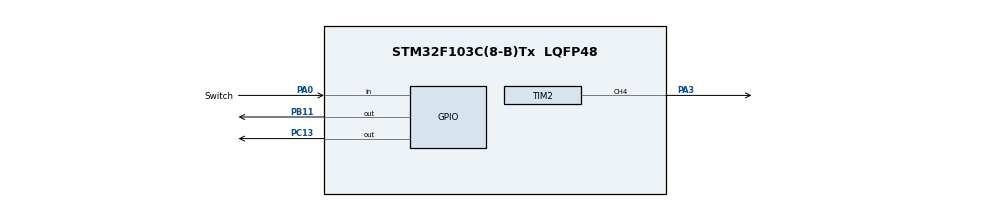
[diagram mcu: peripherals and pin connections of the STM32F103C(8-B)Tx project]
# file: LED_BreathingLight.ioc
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Mcu.Family=STM32F1
Mcu.Name=STM32F103C(8-B)Tx
Mcu.Package=LQFP48
NVIC.PriorityGroup=NVIC_PRIORITYGROUP_4
PA0-WKUP.GPIO_Label=Switch
PA0-WKUP.GPIO_PuPd=GPIO_NOPULL
PA0-WKUP.Signal=GPIO_Input
PA3.Signal=S_TIM2_CH4
PB11.Signal=GPIO_Output
PC13-TAMPER-RTC.GPIO_PuPd=GPIO_NOPULL
PC13-TAMPER-RTC.Signal=GPIO_Output
ProjectManager.HeapSize=0x200
ProjectManager.StackSize=0x400
ProjectManager.TargetToolchain=MDK-ARM V5.27
RCC.APB1Freq_Value=8000000
RCC.APB2CLKDivider=RCC_HCLK_DIV2
RCC.APB2Freq_Value=4000000
RCC.APB2TimFreq_Value=8000000
SH.S_TIM2_CH4.0=TIM2_CH4,PWM Generation4 CH4
TIM2.Channel-PWM\ Generation4\ CH4=TIM_CHANNEL_4
TIM2.Prescaler=1200-1
VP_SYS_VS_ND.Mode=No_Debug
VP_TIM2_VS_ClockSourceINT.Mode=Internal
board=custom

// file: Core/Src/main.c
/* USER CODE BEGIN Header */
/**
  ******************************************************************************
  * @file           : main.c
  * @brief          : Main program body
  ******************************************************************************
  * @attention
  *
  * <h2><center>&copy; Copyright (c) 2020 STMicroelectronics.
  * All rights reserved.</center></h2>
  *
  * This software component is licensed by ST under BSD 3-Clause license,
  * the "License"; You may not use this file except in compliance with the
  * License. You may obtain a copy of the License at:
  *                        opensource.org/licenses/BSD-3-Clause
  *
  ******************************************************************************
  */
/* USER CODE END Header */
#include "main.h"
#include "tim.h"
#include "gpio.h"

void SystemClock_Config(void);

int main(void)
{
  /* USER CODE BEGIN 1 */
	static unsigned char PwmValue = 0;
	static unsigned char Mode = 1;

  /* USER CODE END 1 */

  /* MCU Configuration--------------------------------------------------------*/

  /* Reset of all peripherals, Initializes the Flash interface and the Systick. */
  HAL_Init();

  /* Configure the system clock */
  SystemClock_Config();

  /* Initialize all configured peripherals */
  MX_GPIO_Init();
  MX_TIM2_Init();

  /* Infinite loop */
  /* USER CODE BEGIN WHILE */
  while (1)
  {
		//Yang Shenkai
    /* USER CODE END WHILE */
		switch(HAL_GPIO_ReadPin(GPIOC, GPIO_PIN_13)){         //Task1, use switch to open or turn off the LED PC13
		case 0:
			GPIOC->ODR ^= GPIO_PIN_13;                          //When the pin is 0: 0 ^ 1 = 1  otherwise: 1 ^ 1 = 0
			break;
		case 1:
			GPIOC->ODR ^= GPIO_PIN_13;
			break;
		}

		// Task2 Breathing light
		if (Mode == 1){
			PwmValue++;
		}
		else{
			PwmValue--;
		}

		if (PwmValue ==  99){
			Mode = 0;
		}
		else if (PwmValue == 0){
			Mode = 1;
		}
		__HAL_TIM_SET_COMPARE(&htim2,TIM_CHANNEL_4,PwmValue);
		HAL_Delay(10);

  }
}

void SystemClock_Config(void)
{
  RCC_OscInitTypeDef RCC_OscInitStruct = {0};
  RCC_ClkInitTypeDef RCC_ClkInitStruct = {0};

  /** Initializes the RCC Oscillators according to the specified parameters
  * in the RCC_OscInitTypeDef structure.
  */
  RCC_OscInitStruct.OscillatorType = RCC_OSCILLATORTYPE_HSI;
  RCC_OscInitStruct.HSIState = RCC_HSI_ON;
  RCC_OscInitStruct.HSICalibrationValue = RCC_HSICALIBRATION_DEFAULT;
  RCC_OscInitStruct.PLL.PLLState = RCC_PLL_NONE;
  if (HAL_RCC_OscConfig(&RCC_OscInitStruct) != HAL_OK)
  {
    Error_Handler();
  }
  /** Initializes the CPU, AHB and APB buses clocks
  */
  RCC_ClkInitStruct.ClockType = RCC_CLOCKTYPE_HCLK|RCC_CLOCKTYPE_SYSCLK
                              |RCC_CLOCKTYPE_PCLK1|RCC_CLOCKTYPE_PCLK2;
  RCC_ClkInitStruct.SYSCLKSource = RCC_SYSCLKSOURCE_HSI;
  RCC_ClkInitStruct.AHBCLKDivider = RCC_SYSCLK_DIV1;
  RCC_ClkInitStruct.APB1CLKDivider = RCC_HCLK_DIV1;
  RCC_ClkInitStruct.APB2CLKDivider = RCC_HCLK_DIV2;

  if (HAL_RCC_ClockConfig(&RCC_ClkInitStruct, FLASH_LATENCY_0) != HAL_OK)
  {
    Error_Handler();
  }
}

void Error_Handler(void)
{
}

/************************ (C) COPYRIGHT STMicroelectronics *****END OF FILE****/
